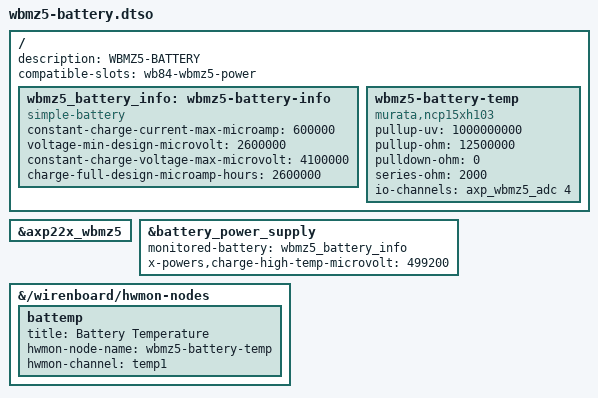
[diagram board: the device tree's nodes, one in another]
/ {
	description = "WBMZ5-BATTERY";
	compatible-slots = "wb84-wbmz5-power";

	fragment-01-declare-battery {
		target-path = "/";

		__overlay__ {
			wbmz5_battery_info: wbmz5-battery-info {
				compatible = "simple-battery";
				constant-charge-current-max-microamp = <600000>;
				voltage-min-design-microvolt = <2600000>;
				constant-charge-voltage-max-microvolt = <4100000>;
				charge-full-design-microamp-hours = <2600000>;
				status = "okay";
			};
		};
	};

	fragment-02-enable-pmic {
		target = <&axp22x_wbmz5>;

		__overlay__ {
			status = "okay";
		};
	};

	fragment-03-enable-battery-ps {
		target = <&battery_power_supply>;

		__overlay__ {
			status = "okay";
			monitored-battery = <&wbmz5_battery_info>;

			// it's 46C-50C high temperature limit
			x-powers,charge-high-temp-microvolt = <499200>;
		};
	};

	fragment-04-temperature {
		target-path = "/";

		__overlay__ {
			/* Huge pullup voltage is here to emulate 80uA constant current source*/
			wbmz5-battery-temp {
				compatible = "murata,ncp15xh103";
				pullup-uv = <1000000000>; // 1E9 uV
				pullup-ohm = <12500000>; // pullup_uv/80
				pulldown-ohm = <0>;
				series-ohm = <2000>;
				io-channels = <&axp_wbmz5_adc 4>;
			};
		};
	};

	fragment-05-temperature-display {
		target-path = "/wirenboard/hwmon-nodes";

		__overlay__ {
			battemp {
				title = "Battery Temperature";
				hwmon-node-name = "wbmz5-battery-temp";
				hwmon-channel = "temp1";
			};
		};
	};
};
